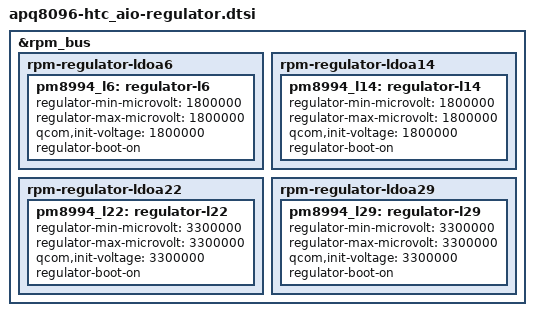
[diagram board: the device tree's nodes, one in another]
/* Copyright (c) 2016, The Linux Foundation. All rights reserved.
 *
 * This program is free software; you can redistribute it and/or modify
 * it under the terms of the GNU General Public License version 2 and
 * only version 2 as published by the Free Software Foundation.
 *
 * This program is distributed in the hope that it will be useful,
 * but WITHOUT ANY WARRANTY; without even the implied warranty of
 * MERCHANTABILITY or FITNESS FOR A PARTICULAR PURPOSE.  See the
 * GNU General Public License for more details.
 */

&rpm_bus {
/* HTC_DISP_START */
    rpm-regulator-ldoa6 {
        status = "okay";
        pm8994_l6: regulator-l6 {
            regulator-min-microvolt = <1800000>;
            regulator-max-microvolt = <1800000>;
            qcom,init-voltage = <1800000>;
            status = "okay";
            regulator-boot-on;
            /delete-property/ regulator-always-on;
        };
    };
    rpm-regulator-ldoa14 {
        status = "okay";
        pm8994_l14: regulator-l14 {
            regulator-min-microvolt = <1800000>;
            regulator-max-microvolt = <1800000>;
            qcom,init-voltage = <1800000>;
            status = "okay";
            regulator-boot-on;
           /delete-property/ regulator-always-on;
        };
    };
    rpm-regulator-ldoa22 {
        status = "okay";
        pm8994_l22: regulator-l22 {
            regulator-min-microvolt = <3300000>;
            regulator-max-microvolt = <3300000>;
            qcom,init-voltage = <3300000>;
            status = "okay";
            regulator-boot-on;
            /delete-property/ regulator-always-on;
        };
    };
    rpm-regulator-ldoa29 {
        status = "okay";
        pm8994_l29: regulator-l29 {
            regulator-min-microvolt = <3300000>;
            regulator-max-microvolt = <3300000>;
            qcom,init-voltage = <3300000>;
            status = "okay";
            regulator-boot-on;
            /delete-property/ regulator-always-on;
        };
    };
/* HTC_DISP_END */
};
